AUTOSAR XML (schema 4-1-2)
standard types defined: uint8, uint8_DataConstr, Boolean, uint16
package /ComponentTypes
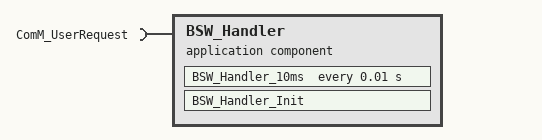
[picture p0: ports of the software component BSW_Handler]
  application sw component type BSW_Handler
    require port ComM_UserRequest: required-com-specs=[GetCurrentComMode, GetMaxComMode, GetRequestedComMode, RequestComMode], required-interface=ComM_UserRequest
    behavior BSW_Handler_InternalBehavior
      timing event TMT_LightCtrl: start-on-event=BSW_Handler_10ms, period=0.01
      init event BSW_Handler_InitEvent: start-on-event=BSW_Handler_Init
      runnable BSW_Handler_10ms
        sync call SC_ComM_UserRequest_GetCurrentComMode: operation=ComM_UserRequest.GetCurrentComMode, timeout=0
        sync call SC_ComM_UserRequest_RequestComMode: operation=ComM_UserRequest.RequestComMode, timeout=0
      runnable BSW_Handler_Init
        sync call SC_ComM_UserRequest_RequestComMode: operation=ComM_UserRequest.RequestComMode, timeout=0
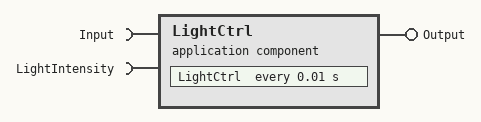
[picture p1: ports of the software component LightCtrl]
  application sw component type LightCtrl
    provide port Output: nonqueued-sender-com-spec{data-element=HeadLight, init-value=0}, provided-interface=Output
    require port Input: nonqueued-receiver-com-spec{data-element=LightSwitch, filter=data-filter-type=ALWAYS, init-value=0}, required-interface=Input
    require port LightIntensity: client-com-spec=LightIntensity, required-interface=LightIntensity
    behavior LightCtrl_InternalBehavior
      timing event TMT_LightCtrl: start-on-event=LightCtrl, period=0.01
      runnable LightCtrl
        data-receive-point-by-arguments:
          access REC_Input_AlexSpecialPort_LightSwitch: accessed-variable=Input.LightSwitch
        data-send-points:
          access SEND_Output_HeadLight: accessed-variable=Output.HeadLight
        sync call SC_LightIntensity_LightIntensity: operation=LightIntensity.LightIntensity, timeout=0
  swc implementation BSW_Handler_Implementation: behavior=BSW_Handler_InternalBehavior
    code-descriptors:
      code Default: artifact-descriptors=autosar-engineering-object={short-label=Default, category=SWSRC}
  swc implementation LightCtrl_Implementation: behavior=LightCtrl_InternalBehavior
    code-descriptors:
      code Default: artifact-descriptors=autosar-engineering-object={short-label=Default, category=SWSRC}
  ecu instance BFC
package /ECUCompositionTypes
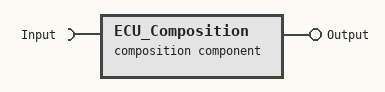
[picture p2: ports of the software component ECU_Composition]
  composition sw component type ECU_Composition
    provide port Output: provided-interface=Output
    require port Input: nonqueued-receiver-com-spec{data-element=LightSwitch, filter=data-filter-type=ALWAYS, init-value=0}, required-interface=Input
    component BSW_Handler: type=BSW_Handler
    component IoHwAb: type=IoHwAb
    component LightCtrl: type=LightCtrl
    connect IoHwAb.LightIntensityPort -> LightCtrl.LightIntensity
    delegate LightCtrl.Input <-> outer port ECU_Composition/Input
    delegate LightCtrl.Output <-> outer port ECU_Composition/Output
package /MICROSAR_Imported/ComM_swc/DataTypes
  impl type ComM_ModeType: compu {0=COMM_NO_COMMUNICATION, 1=COMM_SILENT_COMMUNICATION, 2=COMM_FULL_COMMUNICATION}, range raw 0..3, implementation-data-type=ImplementationDataTypes/uint8
package /MICROSAR_Imported/ComM_swc/Interfaces
  client server interface ComM_UserRequest: is-service=true, service-kind=COM-MANAGER
    4 x operation:
      GetCurrentComMode: possible-error=ComM_UserRequest/E_NOT_OK
        arg ComMode: type=ComM_ModeType, direction=OUT, server-argument-impl-policy=USE-ARGUMENT-TYPE
      GetMaxComMode: possible-error=ComM_UserRequest/E_NOT_OK
        arg ComMode: type=ComM_ModeType, direction=OUT, server-argument-impl-policy=USE-ARGUMENT-TYPE
      GetRequestedComMode: possible-error=ComM_UserRequest/E_NOT_OK
        arg ComMode: type=ComM_ModeType, direction=OUT, server-argument-impl-policy=USE-ARGUMENT-TYPE
      RequestComMode: possible-error=[E_MODE_LIMITATION, ComM_UserRequest/E_NOT_OK]
        arg ComMode: type=ComM_ModeType, direction=IN, server-argument-impl-policy=USE-ARGUMENT-TYPE
    4 x error:
      E_MODE_LIMITATION: error-code=2
      E_MULTIPLE_PNC_ASSIGNED: error-code=3
      E_NO_PNC_ASSIGNED: error-code=4
      E_NOT_OK: error-code=1
package /MICROSAR_SWCS_DEV/IoHwAb_swc/ComponentTypes
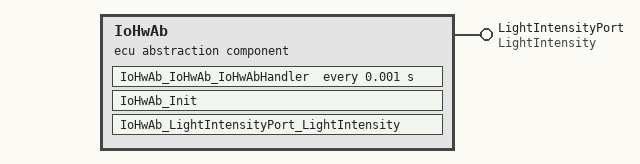
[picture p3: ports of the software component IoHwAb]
  ecu abstraction sw component type IoHwAb
    provide port LightIntensityPort: server-com-spec{operation=LightIntensity, queue-length=1}, provided-interface=LightIntensity
    behavior IoHwAbInternalBehavior
      init event IoHwAb_InitEvent: start-on-event=IoHwAb_Init
      timing event Timer_IoHwAb_IoHwAb_IoHwAbHandler: start-on-event=IoHwAb_IoHwAb_IoHwAbHandler, period=0.001
      operation invoked event OIT_IoHwAb_LightIntensityPort_LightIntensity_LightIntensityPort_LightIntensity: start-on-event=IoHwAb_LightIntensityPort_LightIntensity, operation=LightIntensityPort.LightIntensity
      runnable IoHwAb_Init
      runnable IoHwAb_IoHwAb_IoHwAbHandler: can-be-invoked-concurrently=true
      runnable IoHwAb_LightIntensityPort_LightIntensity: can-be-invoked-concurrently=true  # Runnable Entity for calling the Operation 'LightIntensity' of the Client/Server Port Prototype 'LightIntensityPort'.
  swc implementation IoHwAbImplementation: behavior=IoHwAbInternalBehavior
    code-descriptors:
      code Default: artifact-descriptors=autosar-engineering-object={short-label=Default, category=SWSRC}
package /MICROSAR_SWCS_DEV/IoHwAb_swc/DataTypes/DataConstrs
  range uint16_Constr: raw 0..65535
package /MICROSAR_SWCS_DEV/IoHwAb_swc/Interfaces
  client server interface LightIntensity
    operation LightIntensity
      arg io_signal: type=uint16, direction=OUT, server-argument-impl-policy=USE-ARGUMENT-TYPE
    error E_NOT_OK: error-code=1
package /PortInterfaces
  sender receiver interface Input: invalidation-policy{data-element=LightSwitch, handle-invalid=DONT-INVALIDATE}
    data LightSwitch: type=PlatformTypes/uint8
  sender receiver interface Output: invalidation-policy{data-element=HeadLight, handle-invalid=DONT-INVALIDATE}
    data HeadLight: type=Boolean
package /Systems
  system BFC
    system mapping Mapping
      sw-mappings:
        swc to ecu mapping SwcToBFCMapping: component=[ECU_Composition.BSW_Handler, ECU_Composition.IoHwAb, ECU_Composition.LightCtrl], ecu-instance=BFC
    root-software-compositions:
      root sw composition prototype ECU_Composition: software-composition=ECU_Composition
